AUTOSAR XML (schema 00048)
package /ComponentTypes
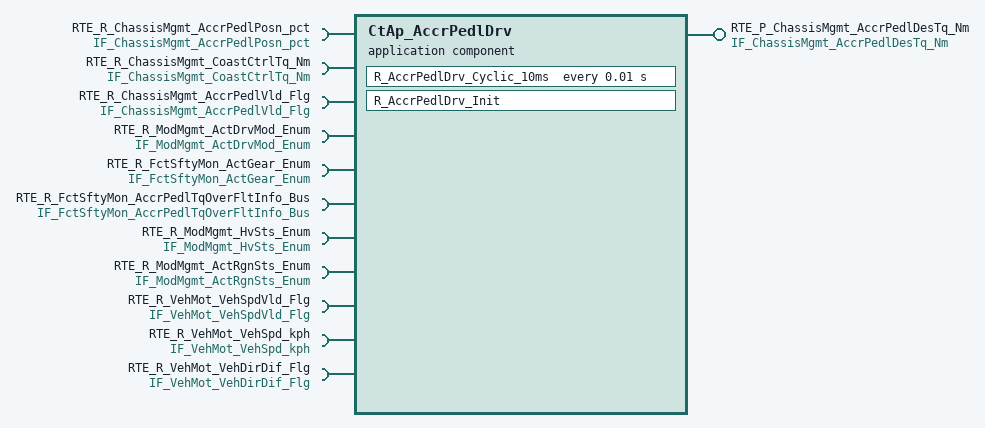
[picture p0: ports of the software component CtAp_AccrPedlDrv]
  application sw component type CtAp_AccrPedlDrv
    provide port RTE_P_ChassisMgmt_AccrPedlDesTq_Nm: nonqueued-sender-com-spec{data-element=tec_ChassisMgmt_AccrPedlDesTq_Nm, init-value=0}, provided-interface=IF_ChassisMgmt_AccrPedlDesTq_Nm
    11 x require port:
      RTE_R_ChassisMgmt_AccrPedlPosn_pct: nonqueued-receiver-com-spec{data-element=tec_ChassisMgmt_AccrPedlPosn_pct, filter=data-filter-type=ALWAYS, init-value=0}, required-interface=IF_ChassisMgmt_AccrPedlPosn_pct
      RTE_R_ChassisMgmt_CoastCtrlTq_Nm: nonqueued-receiver-com-spec{data-element=tec_ChassisMgmt_CoastCtrlDesTq_Nm, filter=data-filter-type=ALWAYS, init-value=0}, required-interface=IF_ChassisMgmt_CoastCtrlTq_Nm
      RTE_R_ChassisMgmt_AccrPedlVld_Flg: nonqueued-receiver-com-spec{data-element=tec_ChassisMgmt_AccrPedlVld_Flg, filter=data-filter-type=ALWAYS, init-value=0}, required-interface=IF_ChassisMgmt_AccrPedlVld_Flg
      RTE_R_ModMgmt_ActDrvMod_Enum: nonqueued-receiver-com-spec{data-element=tec_ModMgmt_ActDrvMod_Enum, filter=data-filter-type=ALWAYS, init-value=0}, required-interface=IF_ModMgmt_ActDrvMod_Enum
      RTE_R_FctSftyMon_ActGear_Enum: nonqueued-receiver-com-spec{data-element=tec_FctSftyMon_ActGear_Enum, filter=data-filter-type=ALWAYS, init-value=0}, required-interface=IF_FctSftyMon_ActGear_Enum
      RTE_R_FctSftyMon_AccrPedlTqOverFltInfo_Bus: nonqueued-receiver-com-spec{data-element=tec_FctSftyMon_AccrPedlTqOverFltInfo_Bus, filter=data-filter-type=ALWAYS, init-value=fields=[FctSftyMon_MonStatAccrPedlTqOverFltInfo:0, FctSftyMon_MonResAccrPedlTqOverFltInfo:0, FctSftyMon_ErrStatAccrPedlTqOverFltInfo:0, FctSftyMon_ErrResAccrPedlTqOverFltInfo:0]}, required-interface=IF_FctSftyMon_AccrPedlTqOverFltInfo_Bus
      RTE_R_ModMgmt_HvSts_Enum: nonqueued-receiver-com-spec{data-element=tec_ModMgmt_HvSts_Enum, filter=data-filter-type=ALWAYS, init-value=0}, required-interface=IF_ModMgmt_HvSts_Enum
      RTE_R_ModMgmt_ActRgnSts_Enum: nonqueued-receiver-com-spec{data-element=tec_ModMgmt_ActRgnSts_Enum, filter=data-filter-type=ALWAYS, init-value=0}, required-interface=IF_ModMgmt_ActRgnSts_Enum
      RTE_R_VehMot_VehSpdVld_Flg: nonqueued-receiver-com-spec{data-element=tec_VehMot_VehSpdVld_Flg, filter=data-filter-type=ALWAYS, init-value=0}, required-interface=IF_VehMot_VehSpdVld_Flg
      RTE_R_VehMot_VehSpd_kph: nonqueued-receiver-com-spec{data-element=tec_VehMot_VehSpd_kph, filter=data-filter-type=ALWAYS, init-value=0}, required-interface=IF_VehMot_VehSpd_kph
      RTE_R_VehMot_VehDirDif_Flg: nonqueued-receiver-com-spec{data-element=tec_VehMot_VehDirDif_Flg, filter=data-filter-type=ALWAYS, init-value=0}, required-interface=IF_VehMot_VehDirDif_Flg
    behavior CtAp_AccrPedlDrv_InternalBehavior
      timing event TMT_R_AccrPedlDrv_Cyclic_10ms: start-on-event=R_AccrPedlDrv_Cyclic_10ms, period=0.01
      init event CtAp_AccrPedlDrv_InitEvent: start-on-event=R_AccrPedlDrv_Init
      runnable R_AccrPedlDrv_Cyclic_10ms
        data-receive-point-by-arguments:
          11 x access:
            REC_RTE_R_ChassisMgmt_AccrPedlPosn_pct_tec_ChassisMgmt_AccrPedlPosn_pct: accessed-variable=RTE_R_ChassisMgmt_AccrPedlPosn_pct.tec_ChassisMgmt_AccrPedlPosn_pct
            REC_RTE_R_ChassisMgmt_AccrPedlVld_Flg_tec_ChassisMgmt_AccrPedlVld_Flg: accessed-variable=RTE_R_ChassisMgmt_AccrPedlVld_Flg.tec_ChassisMgmt_AccrPedlVld_Flg
            REC_RTE_R_ChassisMgmt_CoastCtrlTq_Nm_tec_ChassisMgmt_CoastCtrlDesTq_Nm: accessed-variable=RTE_R_ChassisMgmt_CoastCtrlTq_Nm.tec_ChassisMgmt_CoastCtrlDesTq_Nm
            REC_RTE_R_FctSftyMon_AccrPedlTqOverFltInfo_Bus_tec_FctSftyMon_AccrPedlTqOverFltInfo_Bus: accessed-variable=RTE_R_FctSftyMon_AccrPedlTqOverFltInfo_Bus.tec_FctSftyMon_AccrPedlTqOverFltInfo_Bus
            REC_RTE_R_FctSftyMon_ActGear_Enum_tec_FctSftyMon_ActGear_Enum: accessed-variable=RTE_R_FctSftyMon_ActGear_Enum.tec_FctSftyMon_ActGear_Enum
            REC_RTE_R_ModMgmt_ActDrvMod_Enum_tec_ModMgmt_ActDrvMod_Enum: accessed-variable=RTE_R_ModMgmt_ActDrvMod_Enum.tec_ModMgmt_ActDrvMod_Enum
            REC_RTE_R_ModMgmt_ActRgnSts_Enum_tec_ModMgmt_ActRgnSts_Enum: accessed-variable=RTE_R_ModMgmt_ActRgnSts_Enum.tec_ModMgmt_ActRgnSts_Enum
            REC_RTE_R_ModMgmt_HvSts_Enum_tec_ModMgmt_HvSts_Enum: accessed-variable=RTE_R_ModMgmt_HvSts_Enum.tec_ModMgmt_HvSts_Enum
            REC_RTE_R_VehMot_VehDirDif_Flg_tec_VehMot_VehDirDif_Flg: accessed-variable=RTE_R_VehMot_VehDirDif_Flg.tec_VehMot_VehDirDif_Flg
            REC_RTE_R_VehMot_VehSpdVld_Flg_tec_VehMot_VehSpdVld_Flg: accessed-variable=RTE_R_VehMot_VehSpdVld_Flg.tec_VehMot_VehSpdVld_Flg
            REC_RTE_R_VehMot_VehSpd_kph_tec_VehMot_VehSpd_kph: accessed-variable=RTE_R_VehMot_VehSpd_kph.tec_VehMot_VehSpd_kph
        data-send-points:
          access SEND_RTE_P_ChassisMgmt_AccrPedlDesTq_Nm_tec_ChassisMgmt_AccrPedlDesTq_Nm: accessed-variable=RTE_P_ChassisMgmt_AccrPedlDesTq_Nm.tec_ChassisMgmt_AccrPedlDesTq_Nm
      runnable R_AccrPedlDrv_Init
  swc implementation CtAp_AccrPedlDrv_Implementation: behavior=CtAp_AccrPedlDrv_InternalBehavior
